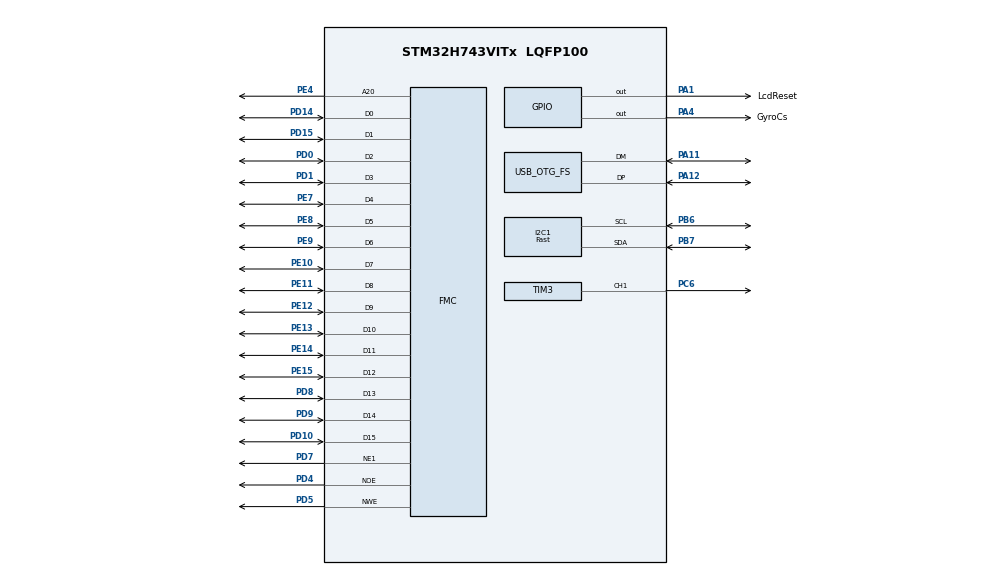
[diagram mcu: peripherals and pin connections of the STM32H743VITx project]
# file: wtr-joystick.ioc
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CORTEX_M7.AccessPermission-Cortex_Memory_Protection_Unit_Region0_Settings=MPU_REGION_FULL_ACCESS
CORTEX_M7.AccessPermission-Cortex_Memory_Protection_Unit_Region1_Settings=MPU_REGION_FULL_ACCESS
CORTEX_M7.AccessPermission_S-Cortex_Memory_Protection_Unit_Region1_Settings_S=MPU_REGION_FULL_ACCESS
CORTEX_M7.AccessPermission_S-Cortex_Memory_Protection_Unit_Region2_Settings_S=MPU_REGION_FULL_ACCESS
CORTEX_M7.AccessPermission_S-Cortex_Memory_Protection_Unit_Region3_Settings_S=MPU_REGION_FULL_ACCESS
CORTEX_M7.AccessPermission_S-Cortex_Memory_Protection_Unit_Region4_Settings_S=MPU_REGION_FULL_ACCESS
CORTEX_M7.AccessPermission_S-Cortex_Memory_Protection_Unit_Region5_Settings_S=MPU_REGION_FULL_ACCESS
CORTEX_M7.AccessPermission_Spec=MPU_REGION_NO_ACCESS
CORTEX_M7.BaseAddress-Cortex_Memory_Protection_Unit_Region0_Settings=0x20000000
CORTEX_M7.BaseAddress-Cortex_Memory_Protection_Unit_Region1_Settings=0x24000000
CORTEX_M7.BaseAddress-Cortex_Memory_Protection_Unit_Region2_Settings=0x60000000
CORTEX_M7.BaseAddress_S-Cortex_Memory_Protection_Unit_Region1_Settings_S=0x24000000
CORTEX_M7.BaseAddress_S-Cortex_Memory_Protection_Unit_Region2_Settings_S=0x60000000
CORTEX_M7.BaseAddress_S-Cortex_Memory_Protection_Unit_Region3_Settings_S=0x20000000
CORTEX_M7.BaseAddress_S-Cortex_Memory_Protection_Unit_Region4_Settings_S=0x30000000
CORTEX_M7.BaseAddress_S-Cortex_Memory_Protection_Unit_Region5_Settings_S=0x38000000
CORTEX_M7.BaseAddress_Spec=0x0
CORTEX_M7.CPU_DCache=Enabled
CORTEX_M7.CPU_ICache=Enabled
CORTEX_M7.DisableExec_S-Cortex_Memory_Protection_Unit_Region2_Settings_S=MPU_INSTRUCTION_ACCESS_DISABLE
CORTEX_M7.DisableExec_Spec=MPU_INSTRUCTION_ACCESS_DISABLE
CORTEX_M7.Enable-Cortex_Memory_Protection_Unit_Region0_Settings=MPU_REGION_ENABLE
CORTEX_M7.Enable-Cortex_Memory_Protection_Unit_Region1_Settings=MPU_REGION_ENABLE
CORTEX_M7.Enable-Cortex_Memory_Protection_Unit_Region2_Settings=MPU_REGION_ENABLE
CORTEX_M7.Enable_S-Cortex_Memory_Protection_Unit_Region1_Settings_S=MPU_REGION_ENABLE
CORTEX_M7.Enable_S-Cortex_Memory_Protection_Unit_Region2_Settings_S=MPU_REGION_ENABLE
CORTEX_M7.Enable_S-Cortex_Memory_Protection_Unit_Region3_Settings_S=MPU_REGION_ENABLE
CORTEX_M7.Enable_S-Cortex_Memory_Protection_Unit_Region4_Settings_S=MPU_REGION_ENABLE
CORTEX_M7.Enable_S-Cortex_Memory_Protection_Unit_Region5_Settings_S=MPU_REGION_ENABLE
CORTEX_M7.IsBufferable-Cortex_Memory_Protection_Unit_Region0_Settings=MPU_ACCESS_BUFFERABLE
CORTEX_M7.IsBufferable_S-Cortex_Memory_Protection_Unit_Region3_Settings_S=MPU_ACCESS_BUFFERABLE
CORTEX_M7.IsBufferable_S-Cortex_Memory_Protection_Unit_Region5_Settings_S=MPU_ACCESS_NOT_BUFFERABLE
CORTEX_M7.IsBufferable_Spec=MPU_ACCESS_NOT_BUFFERABLE
CORTEX_M7.IsCacheable-Cortex_Memory_Protection_Unit_Region0_Settings=MPU_ACCESS_CACHEABLE
CORTEX_M7.IsCacheable-Cortex_Memory_Protection_Unit_Region1_Settings=MPU_ACCESS_CACHEABLE
CORTEX_M7.IsCacheable_S-Cortex_Memory_Protection_Unit_Region1_Settings_S=MPU_ACCESS_CACHEABLE
CORTEX_M7.IsCacheable_S-Cortex_Memory_Protection_Unit_Region3_Settings_S=MPU_ACCESS_CACHEABLE
CORTEX_M7.IsCacheable_S-Cortex_Memory_Protection_Unit_Region4_Settings_S=MPU_ACCESS_CACHEABLE
CORTEX_M7.IsCacheable_S-Cortex_Memory_Protection_Unit_Region5_Settings_S=MPU_ACCESS_CACHEABLE
CORTEX_M7.IsCacheable_Spec=MPU_ACCESS_NOT_CACHEABLE
CORTEX_M7.IsShareable_S-Cortex_Memory_Protection_Unit_Region4_Settings_S=MPU_ACCESS_SHAREABLE
CORTEX_M7.IsShareable_S-Cortex_Memory_Protection_Unit_Region5_Settings_S=MPU_ACCESS_SHAREABLE
CORTEX_M7.IsShareable_Spec=MPU_ACCESS_SHAREABLE
CORTEX_M7.MPU_Control=MPU_PRIVILEGED_DEFAULT
CORTEX_M7.Size-Cortex_Memory_Protection_Unit_Region0_Settings=MPU_REGION_SIZE_128KB
CORTEX_M7.Size-Cortex_Memory_Protection_Unit_Region1_Settings=MPU_REGION_SIZE_512KB
CORTEX_M7.Size_S-Cortex_Memory_Protection_Unit_Region1_Settings_S=MPU_REGION_SIZE_512KB
CORTEX_M7.Size_S-Cortex_Memory_Protection_Unit_Region2_Settings_S=MPU_REGION_SIZE_1GB
CORTEX_M7.Size_S-Cortex_Memory_Protection_Unit_Region3_Settings_S=MPU_REGION_SIZE_128KB
CORTEX_M7.Size_S-Cortex_Memory_Protection_Unit_Region4_Settings_S=MPU_REGION_SIZE_512KB
CORTEX_M7.Size_S-Cortex_Memory_Protection_Unit_Region5_Settings_S=MPU_REGION_SIZE_64KB
CORTEX_M7.Size_Spec=MPU_REGION_SIZE_4GB
CORTEX_M7.SubRegionDisable_Spec=0x87
CORTEX_M7.TypeExtField-Cortex_Memory_Protection_Unit_Region0_Settings=MPU_TEX_LEVEL1
CORTEX_M7.TypeExtField_S-Cortex_Memory_Protection_Unit_Region3_Settings_S=MPU_TEX_LEVEL1
CORTEX_M7.TypeExtField_S-Cortex_Memory_Protection_Unit_Region4_Settings_S=MPU_TEX_LEVEL0
CORTEX_M7.TypeExtField_S-Cortex_Memory_Protection_Unit_Region5_Settings_S=MPU_TEX_LEVEL0
CORTEX_M7.TypeExtField_Spec=MPU_TEX_LEVEL0
CORTEX_M7.default_mode_Activation=1
Dma.MEMTOMEM.0.Direction=DMA_MEMORY_TO_MEMORY
Dma.MEMTOMEM.0.EventEnable=DISABLE
Dma.MEMTOMEM.0.FIFOMode=DMA_FIFOMODE_ENABLE
Dma.MEMTOMEM.0.FIFOThreshold=DMA_FIFO_THRESHOLD_FULL
Dma.MEMTOMEM.0.Instance=DMA1_Stream0
Dma.MEMTOMEM.0.MemBurst=DMA_MBURST_SINGLE
Dma.MEMTOMEM.0.MemDataAlignment=DMA_MDATAALIGN_HALFWORD
Dma.MEMTOMEM.0.MemInc=DMA_MINC_DISABLE
Dma.MEMTOMEM.0.Mode=DMA_NORMAL
Dma.MEMTOMEM.0.PeriphBurst=DMA_PBURST_SINGLE
Dma.MEMTOMEM.0.PeriphDataAlignment=DMA_PDATAALIGN_HALFWORD
Dma.MEMTOMEM.0.PeriphInc=DMA_PINC_ENABLE
Dma.MEMTOMEM.0.Polarity=HAL_DMAMUX_REQ_GEN_RISING
Dma.MEMTOMEM.0.Priority=DMA_PRIORITY_LOW
Dma.MEMTOMEM.0.RequestNumber=1
Dma.MEMTOMEM.0.SignalID=NONE
Dma.MEMTOMEM.0.SyncEnable=DISABLE
Dma.MEMTOMEM.0.SyncPolarity=HAL_DMAMUX_SYNC_NO_EVENT
Dma.MEMTOMEM.0.SyncRequestNumber=1
Dma.MEMTOMEM.0.SyncSignalID=NONE
Dma.Request0=MEMTOMEM
FMC.AddressSetupTime1=0
FMC.BusTurnAroundDuration1=0
FMC.DataSetupTime1=110
FMC.ExtendedAddressSetupTime1=0
FMC.ExtendedBusTurnAroundDuration1=0
FMC.ExtendedDataSetupTime1=5
FMC.ExtendedMode1=FMC_EXTENDED_MODE_ENABLE
FREERTOS.Tasks01=defaultTask,24,512,StartDefaultTask,As weak,NULL,Dynamic,NULL,NULL
FREERTOS.configCHECK_FOR_STACK_OVERFLOW=2
FREERTOS.configENABLE_FPU=1
FREERTOS.configGENERATE_RUN_TIME_STATS=1
FREERTOS.configMAX_TASK_NAME_LEN=32
FREERTOS.configMINIMAL_STACK_SIZE=256
FREERTOS.configRECORD_STACK_HIGH_ADDRESS=1
FREERTOS.configTOTAL_HEAP_SIZE=131072
FREERTOS.configUSE_NEWLIB_REENTRANT=1
FREERTOS.configUSE_POSIX_ERRNO=1
FREERTOS.configUSE_STATS_FORMATTING_FUNCTIONS=1
FREERTOS.configUSE_TICK_HOOK=1
FREERTOS.copyHeapFile=1
I2C1.I2C_Speed_Mode=I2C_Fast
I2C1.Timing=0x00B03FDB
Mcu.Family=STM32H7
Mcu.Name=STM32H743VITx
Mcu.Package=LQFP100
NVIC.DMA1_Stream0_IRQn=true\:5\:0\:true\:false\:true\:true\:true\:true\:true
NVIC.OTG_FS_IRQn=true\:11\:0\:true\:false\:true\:true\:false\:true\:true
NVIC.PriorityGroup=NVIC_PRIORITYGROUP_4
NVIC.TIM7_IRQn=true\:1\:0\:true\:false\:true\:false\:false\:true\:true
NVIC.TimeBase=TIM7_IRQn
NVIC.TimeBaseIP=TIM7
PA1.GPIO_Label=LcdReset
PA1.PinState=GPIO_PIN_SET
PA1.Signal=GPIO_Output
PA11.Mode=Device_Only
PA11.Signal=USB_OTG_FS_DM
PA12.Mode=Device_Only
PA12.Signal=USB_OTG_FS_DP
PA13\ (JTMS/SWDIO).Mode=Serial_Wire
PA13\ (JTMS/SWDIO).Signal=DEBUG_JTMS-SWDIO
PA14\ (JTCK/SWCLK).Mode=Serial_Wire
PA14\ (JTCK/SWCLK).Signal=DEBUG_JTCK-SWCLK
PA4.GPIO_Label=GyroCs
PA4.Signal=GPIO_Output
PA5.Signal=SPI1_SCK
PA6.Signal=SPI1_MISO
PA7.Signal=SPI1_MOSI
PB6.Mode=I2C
PB6.Signal=I2C1_SCL
PB7.Mode=I2C
PB7.Signal=I2C1_SDA
PC14-OSC32_IN\ (OSC32_IN).Mode=LSE-External-Oscillator
PC14-OSC32_IN\ (OSC32_IN).Signal=RCC_OSC32_IN
PC15-OSC32_OUT\ (OSC32_OUT).Mode=LSE-External-Oscillator
PC15-OSC32_OUT\ (OSC32_OUT).Signal=RCC_OSC32_OUT
PC6.Signal=S_TIM3_CH1
PD0.Signal=FMC_D2_DA2
PD1.Signal=FMC_D3_DA3
PD10.Signal=FMC_D15_DA15
PD14.Signal=FMC_D0_DA0
PD15.Signal=FMC_D1_DA1
PD4.Signal=FMC_NOE
PD5.Signal=FMC_NWE
PD7.Mode=NorPsramChipSelect1_1
PD7.Signal=FMC_NE1
PD8.Signal=FMC_D13_DA13
PD9.Signal=FMC_D14_DA14
PE10.Signal=FMC_D7_DA7
PE11.Signal=FMC_D8_DA8
PE12.Signal=FMC_D9_DA9
PE13.Signal=FMC_D10_DA10
PE14.Signal=FMC_D11_DA11
PE15.Signal=FMC_D12_DA12
PE4.Signal=FMC_A20
PE7.Signal=FMC_D4_DA4
PE8.Signal=FMC_D5_DA5
PE9.Signal=FMC_D6_DA6
PH0-OSC_IN\ (PH0).Mode=HSE-External-Oscillator
PH0-OSC_IN\ (PH0).Signal=RCC_OSC_IN
PH1-OSC_OUT\ (PH1).Mode=HSE-External-Oscillator
PH1-OSC_OUT\ (PH1).Signal=RCC_OSC_OUT
ProjectManager.HeapSize=0x1000
ProjectManager.StackSize=0x1000
ProjectManager.TargetToolchain=STM32CubeIDE
RCC.ADCFreq_Value=50390625
RCC.APB1Freq_Value=120000000
RCC.APB2Freq_Value=120000000
RCC.APB3Freq_Value=120000000
RCC.APB4Freq_Value=120000000
RCC.CortexFreq_Value=480000000
RCC.D1PPRE=RCC_APB3_DIV2
RCC.D2PPRE1=RCC_APB1_DIV2
RCC.D2PPRE2=RCC_APB2_DIV2
RCC.D3PPRE=RCC_APB4_DIV2
RCC.DIVM1=5
RCC.DIVN1=192
RCC.DIVQ1=20
RCC.DIVR1=4
RCC.HCLKFreq_Value=240000000
RCC.HPRE=RCC_HCLK_DIV2
RCC.PLLSourceVirtual=RCC_PLLSOURCE_HSE
RCC.ProductRev=revV
RCC.SYSCLKFreq_VALUE=480000000
RCC.SYSCLKSource=RCC_SYSCLKSOURCE_PLLCLK
RCC.USBFreq_Value=48000000
SH.FMC_A20.0=FMC_A20,A20_1
SH.FMC_D0_DA0.0=FMC_D0,16b-d1
SH.FMC_D10_DA10.0=FMC_D10,16b-d1
SH.FMC_D11_DA11.0=FMC_D11,16b-d1
SH.FMC_D12_DA12.0=FMC_D12,16b-d1
SH.FMC_D13_DA13.0=FMC_D13,16b-d1
SH.FMC_D14_DA14.0=FMC_D14,16b-d1
SH.FMC_D15_DA15.0=FMC_D15,16b-d1
SH.FMC_D1_DA1.0=FMC_D1,16b-d1
SH.FMC_D2_DA2.0=FMC_D2,16b-d1
SH.FMC_D3_DA3.0=FMC_D3,16b-d1
SH.FMC_D4_DA4.0=FMC_D4,16b-d1
SH.FMC_D5_DA5.0=FMC_D5,16b-d1
SH.FMC_D6_DA6.0=FMC_D6,16b-d1
SH.FMC_D7_DA7.0=FMC_D7,16b-d1
SH.FMC_D8_DA8.0=FMC_D8,16b-d1
SH.FMC_D9_DA9.0=FMC_D9,16b-d1
SH.FMC_NOE.0=FMC_NOE,Lcd1
SH.FMC_NWE.0=FMC_NWE,Lcd1
SH.S_TIM3_CH1.0=TIM3_CH1,PWM Generation1 CH1
TIM3.AutoReloadPreload=TIM_AUTORELOAD_PRELOAD_ENABLE
TIM3.Channel-PWM\ Generation1\ CH1=TIM_CHANNEL_1
TIM3.Period=1000-1
TIM3.Prescaler=60-1
TIM3.Pulse-PWM\ Generation1\ CH1=500
USB_DEVICE.CLASS_NAME_FS=CDC
USB_DEVICE.VirtualMode-CDC_FS=Cdc
USB_DEVICE.VirtualModeFS=Cdc_FS
USB_OTG_FS.VirtualMode=Device_Only
VP_FREERTOS_VS_CMSIS_V2.Mode=CMSIS_V2
VP_SYS_VS_tim7.Mode=TIM7
VP_TIM3_VS_ClockSourceINT.Mode=Internal
VP_USB_DEVICE_VS_USB_DEVICE_CDC_FS.Mode=CDC_FS
board=custom

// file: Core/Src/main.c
/* USER CODE BEGIN Header */
/**
  ******************************************************************************
  * @file           : main.c
  * @brief          : Main program body
  ******************************************************************************
  * @attention
  *
  * Copyright (c) 2022 STMicroelectronics.
  * All rights reserved.
  *
  * This software is licensed under terms that can be found in the LICENSE file
  * in the root directory of this software component.
  * If no LICENSE file comes with this software, it is provided AS-IS.
  *
  ******************************************************************************
  */
/* USER CODE END Header */
#include "main.h"
#include "cmsis_os.h"
#include "dma.h"
#include "i2c.h"
#include "tim.h"
#include "usb_device.h"
#include "gpio.h"
#include "fmc.h"

void SystemClock_Config(void);
static void MPU_Config(void);
void MX_FREERTOS_Init(void);

int main(void)
{
  /* USER CODE BEGIN 1 */
  extern void SysInit();
  SysInit();
  /* USER CODE END 1 */

  /* MPU Configuration--------------------------------------------------------*/
  MPU_Config();

  /* Enable I-Cache---------------------------------------------------------*/
  SCB_EnableICache();

  /* Enable D-Cache---------------------------------------------------------*/
  SCB_EnableDCache();

  /* MCU Configuration--------------------------------------------------------*/

  /* Reset of all peripherals, Initializes the Flash interface and the Systick. */
  HAL_Init();

  /* Configure the system clock */
  SystemClock_Config();

  /* Initialize all configured peripherals */
  MX_GPIO_Init();
  MX_DMA_Init();
  MX_TIM3_Init();
  MX_FMC_Init();
  MX_I2C1_Init();

  /* Init scheduler */
  osKernelInitialize();  /* Call init function for freertos objects (in freertos.c) */
  MX_FREERTOS_Init();

  /* Start scheduler */
  osKernelStart();

  /* We should never get here as control is now taken by the scheduler */
  /* Infinite loop */
  while (1)
  {

  }
}

void SystemClock_Config(void)
{
  RCC_OscInitTypeDef RCC_OscInitStruct = {0};
  RCC_ClkInitTypeDef RCC_ClkInitStruct = {0};

  /** Supply configuration update enable
  */
  HAL_PWREx_ConfigSupply(PWR_LDO_SUPPLY);

  /** Configure the main internal regulator output voltage
  */
  __HAL_PWR_VOLTAGESCALING_CONFIG(PWR_REGULATOR_VOLTAGE_SCALE1);

  while(!__HAL_PWR_GET_FLAG(PWR_FLAG_VOSRDY)) {}

  __HAL_RCC_SYSCFG_CLK_ENABLE();
  __HAL_PWR_VOLTAGESCALING_CONFIG(PWR_REGULATOR_VOLTAGE_SCALE0);

  while(!__HAL_PWR_GET_FLAG(PWR_FLAG_VOSRDY)) {}

  /** Initializes the RCC Oscillators according to the specified parameters
  * in the RCC_OscInitTypeDef structure.
  */
  RCC_OscInitStruct.OscillatorType = RCC_OSCILLATORTYPE_HSE;
  RCC_OscInitStruct.HSEState = RCC_HSE_ON;
  RCC_OscInitStruct.PLL.PLLState = RCC_PLL_ON;
  RCC_OscInitStruct.PLL.PLLSource = RCC_PLLSOURCE_HSE;
  RCC_OscInitStruct.PLL.PLLM = 5;
  RCC_OscInitStruct.PLL.PLLN = 192;
  RCC_OscInitStruct.PLL.PLLP = 2;
  RCC_OscInitStruct.PLL.PLLQ = 20;
  RCC_OscInitStruct.PLL.PLLR = 4;
  RCC_OscInitStruct.PLL.PLLRGE = RCC_PLL1VCIRANGE_2;
  RCC_OscInitStruct.PLL.PLLVCOSEL = RCC_PLL1VCOWIDE;
  RCC_OscInitStruct.PLL.PLLFRACN = 0;
  if (HAL_RCC_OscConfig(&RCC_OscInitStruct) != HAL_OK)
  {
    Error_Handler();
  }

  /** Initializes the CPU, AHB and APB buses clocks
  */
  RCC_ClkInitStruct.ClockType = RCC_CLOCKTYPE_HCLK|RCC_CLOCKTYPE_SYSCLK
                              |RCC_CLOCKTYPE_PCLK1|RCC_CLOCKTYPE_PCLK2
                              |RCC_CLOCKTYPE_D3PCLK1|RCC_CLOCKTYPE_D1PCLK1;
  RCC_ClkInitStruct.SYSCLKSource = RCC_SYSCLKSOURCE_PLLCLK;
  RCC_ClkInitStruct.SYSCLKDivider = RCC_SYSCLK_DIV1;
  RCC_ClkInitStruct.AHBCLKDivider = RCC_HCLK_DIV2;
  RCC_ClkInitStruct.APB3CLKDivider = RCC_APB3_DIV2;
  RCC_ClkInitStruct.APB1CLKDivider = RCC_APB1_DIV2;
  RCC_ClkInitStruct.APB2CLKDivider = RCC_APB2_DIV2;
  RCC_ClkInitStruct.APB4CLKDivider = RCC_APB4_DIV2;

  if (HAL_RCC_ClockConfig(&RCC_ClkInitStruct, FLASH_LATENCY_4) != HAL_OK)
  {
    Error_Handler();
  }
}

/* MPU Configuration */

void MPU_Config(void)
{
  MPU_Region_InitTypeDef MPU_InitStruct = {0};

  /* Disables the MPU */
  HAL_MPU_Disable();

  /** Initializes and configures the Region and the memory to be protected
  */
  MPU_InitStruct.Enable = MPU_REGION_ENABLE;
  MPU_InitStruct.Number = MPU_REGION_NUMBER0;
  MPU_InitStruct.BaseAddress = 0x0;
  MPU_InitStruct.Size = MPU_REGION_SIZE_4GB;
  MPU_InitStruct.SubRegionDisable = 0x87;
  MPU_InitStruct.TypeExtField = MPU_TEX_LEVEL0;
  MPU_InitStruct.AccessPermission = MPU_REGION_NO_ACCESS;
  MPU_InitStruct.DisableExec = MPU_INSTRUCTION_ACCESS_DISABLE;
  MPU_InitStruct.IsShareable = MPU_ACCESS_SHAREABLE;
  MPU_InitStruct.IsCacheable = MPU_ACCESS_NOT_CACHEABLE;
  MPU_InitStruct.IsBufferable = MPU_ACCESS_NOT_BUFFERABLE;

  HAL_MPU_ConfigRegion(&MPU_InitStruct);

  /** Initializes and configures the Region and the memory to be protected
  */
  MPU_InitStruct.Number = MPU_REGION_NUMBER1;
  MPU_InitStruct.BaseAddress = 0x24000000;
  MPU_InitStruct.Size = MPU_REGION_SIZE_512KB;
  MPU_InitStruct.SubRegionDisable = 0x0;
  MPU_InitStruct.AccessPermission = MPU_REGION_FULL_ACCESS;
  MPU_InitStruct.DisableExec = MPU_INSTRUCTION_ACCESS_ENABLE;
  MPU_InitStruct.IsShareable = MPU_ACCESS_NOT_SHAREABLE;
  MPU_InitStruct.IsCacheable = MPU_ACCESS_CACHEABLE;

  HAL_MPU_ConfigRegion(&MPU_InitStruct);

  /** Initializes and configures the Region and the memory to be protected
  */
  MPU_InitStruct.Number = MPU_REGION_NUMBER2;
  MPU_InitStruct.BaseAddress = 0x60000000;
  MPU_InitStruct.Size = MPU_REGION_SIZE_1GB;
  MPU_InitStruct.DisableExec = MPU_INSTRUCTION_ACCESS_DISABLE;
  MPU_InitStruct.IsCacheable = MPU_ACCESS_NOT_CACHEABLE;

  HAL_MPU_ConfigRegion(&MPU_InitStruct);

  /** Initializes and configures the Region and the memory to be protected
  */
  MPU_InitStruct.Number = MPU_REGION_NUMBER3;
  MPU_InitStruct.BaseAddress = 0x20000000;
  MPU_InitStruct.Size = MPU_REGION_SIZE_128KB;
  MPU_InitStruct.TypeExtField = MPU_TEX_LEVEL1;
  MPU_InitStruct.DisableExec = MPU_INSTRUCTION_ACCESS_ENABLE;
  MPU_InitStruct.IsCacheable = MPU_ACCESS_CACHEABLE;
  MPU_InitStruct.IsBufferable = MPU_ACCESS_BUFFERABLE;

  HAL_MPU_ConfigRegion(&MPU_InitStruct);

  /** Initializes and configures the Region and the memory to be protected
  */
  MPU_InitStruct.Number = MPU_REGION_NUMBER4;
  MPU_InitStruct.BaseAddress = 0x30000000;
  MPU_InitStruct.Size = MPU_REGION_SIZE_512KB;
  MPU_InitStruct.TypeExtField = MPU_TEX_LEVEL0;
  MPU_InitStruct.IsShareable = MPU_ACCESS_SHAREABLE;
  MPU_InitStruct.IsBufferable = MPU_ACCESS_NOT_BUFFERABLE;

  HAL_MPU_ConfigRegion(&MPU_InitStruct);

  /** Initializes and configures the Region and the memory to be protected
  */
  MPU_InitStruct.Number = MPU_REGION_NUMBER5;
  MPU_InitStruct.BaseAddress = 0x38000000;
  MPU_InitStruct.Size = MPU_REGION_SIZE_64KB;

  HAL_MPU_ConfigRegion(&MPU_InitStruct);
  /* Enables the MPU */
  HAL_MPU_Enable(MPU_PRIVILEGED_DEFAULT);

}

void HAL_TIM_PeriodElapsedCallback(TIM_HandleTypeDef *htim)
{
  if (htim->Instance == TIM7) {
    HAL_IncTick();
  }
}

void Error_Handler(void)
{
  __disable_irq();
  while (1)
  {
  }
}

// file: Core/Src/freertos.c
/* USER CODE BEGIN Header */
/**
  ******************************************************************************
  * File Name          : freertos.c
  * Description        : Code for freertos applications
  ******************************************************************************
  * @attention
  *
  * Copyright (c) 2023 STMicroelectronics.
  * All rights reserved.
  *
  * This software is licensed under terms that can be found in the LICENSE file
  * in the root directory of this software component.
  * If no LICENSE file comes with this software, it is provided AS-IS.
  *
  ******************************************************************************
  */
/* USER CODE END Header */

#include "FreeRTOS.h"
#include "task.h"
#include "main.h"
#include "cmsis_os.h"

/* Definitions for defaultTask */
osThreadId_t defaultTaskHandle;
const osThreadAttr_t defaultTask_attributes = {
  .name = "defaultTask",
  .stack_size = 512 * 4,
  .priority = (osPriority_t) osPriorityNormal,
};

void StartDefaultTask(void *argument);

extern void MX_USB_DEVICE_Init(void);
void MX_FREERTOS_Init(void); /* (MISRA C 2004 rule 8.1) */

/* Hook prototypes */
void configureTimerForRunTimeStats(void);
unsigned long getRunTimeCounterValue(void);
void vApplicationTickHook(void);
void vApplicationStackOverflowHook(xTaskHandle xTask, signed char *pcTaskName);

/* USER CODE BEGIN 1 */
/* Functions needed when configGENERATE_RUN_TIME_STATS is on */
__weak void configureTimerForRunTimeStats(void)
{

}

__weak unsigned long getRunTimeCounterValue(void)
{
return 0;
}
/* USER CODE END 1 */

/* USER CODE BEGIN 3 */
// void vApplicationTickHook( void )
// {
//    /* This function will be called by each tick interrupt if
//    configUSE_TICK_HOOK is set to 1 in FreeRTOSConfig.h. User code can be
//    added here, but the tick hook is called from an interrupt context, so
//    code must not attempt to block, and only the interrupt safe FreeRTOS API
//    functions can be used (those that end in FromISR()). */
// }
/* USER CODE END 3 */

/* USER CODE BEGIN 4 */
void vApplicationStackOverflowHook(xTaskHandle xTask, signed char *pcTaskName)
{
   /* Run time stack overflow checking is performed if
   configCHECK_FOR_STACK_OVERFLOW is defined to 1 or 2. This hook function is
   called if a stack overflow is detected. */
}
/* USER CODE END 4 */

void MX_FREERTOS_Init(void) {

  /* Create the thread(s) */
  /* creation of defaultTask */
  defaultTaskHandle = osThreadNew(StartDefaultTask, NULL, &defaultTask_attributes);

}

__weak void StartDefaultTask(void *argument)
{
  /* init code for USB_DEVICE */
  MX_USB_DEVICE_Init();
  for(;;)
  {
    osDelay(1);
  }
}
